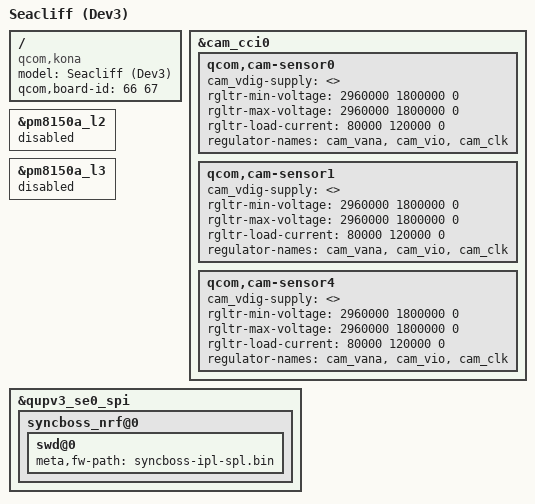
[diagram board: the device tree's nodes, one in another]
// SPDX-License-Identifier: GPL-2.0

/dts-v1/;
/plugin/;

#include "seacliff.dtsi"
#include "seacliff-adc-usbc.dtsi"

/ {
	model = "Seacliff (Dev3)";
	compatible = "qcom,kona";
	qcom,board-id = <66 67>;
};

&cam_cci0 {
	qcom,cam-sensor0 {
		cam_vdig-supply = <>;
		rgltr-min-voltage = <2960000 1800000 0>;
		rgltr-max-voltage = <2960000 1800000 0>;
		rgltr-load-current = <80000 120000 0>;
		regulator-names = "cam_vana", "cam_vio",
			"cam_clk";
	};

	qcom,cam-sensor1 {
		cam_vdig-supply = <>;
		rgltr-min-voltage = <2960000 1800000 0>;
		rgltr-max-voltage = <2960000 1800000 0>;
		rgltr-load-current = <80000 120000 0>;
		regulator-names = "cam_vana", "cam_vio",
			"cam_clk";
	};

	qcom,cam-sensor4 {
		cam_vdig-supply = <>;
		rgltr-min-voltage = <2960000 1800000 0>;
		rgltr-max-voltage = <2960000 1800000 0>;
		rgltr-load-current = <80000 120000 0>;
		regulator-names = "cam_vana", "cam_vio",
			"cam_clk";
	};
};

&pm8150a_l2 {
	status = "disabled";
};

&pm8150a_l3 {
	status = "disabled";
};

&qupv3_se0_spi {
	syncboss_nrf@0 {
		swd@0 {
			meta,fw-path = "syncboss-ipl-spl.bin";
		};
	};
};
